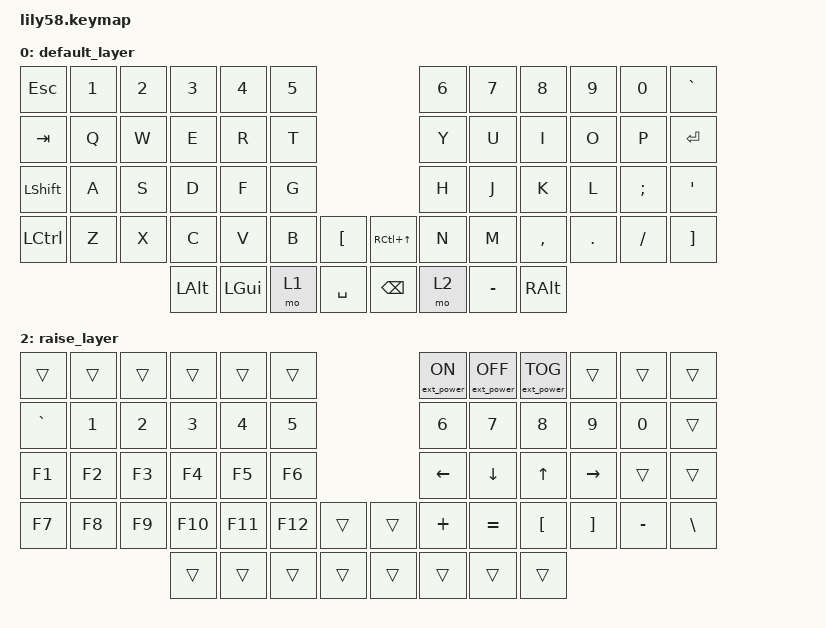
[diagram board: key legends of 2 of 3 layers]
/*
 * Copyright (c) 2020 The ZMK Contributors
 *
 * SPDX-License-Identifier: MIT
 */

#include <behaviors.dtsi>
#include <dt-bindings/zmk/bt.h>
#include <dt-bindings/zmk/ext_power.h>
#include <dt-bindings/zmk/keys.h>

/ {
    behaviors {
        td_mt: tap_dance_mod_tap {
            compatible = "zmk,behavior-tap-dance";
            label = "TAP_DANCE_MOD_TAP";
            #binding-cells = <0>;
            tapping-term-ms = <80>;
            bindings = <&mt LSHIFT CAPSLOCK>, <&kp LCTRL>;
        };

        td0: tap_dance_0 {
            compatible = "zmk,behavior-tap-dance";
            label = "TAP_DANCE_0";
            #binding-cells = <0>;
            tapping-term-ms = <80>;
            bindings = <&kp RSHIFT>, <&kp LCTRL>, <&kp ENTER>;
        };
    };

    macros {
        menu: menu {
            compatible = "zmk,behavior-macro";
            label = "new_macro";
            #binding-cells = <0>;
            bindings = <&kp RGUI &kp D>;
        };
    };

    keymap {
        compatible = "zmk,keymap";

        default_layer {
            // ------------------------------------------------------------------------------------------------------------
            // |  ESC  |  1  |  2  |  3   |  4   |  5   |                   |  6   |  7    |  8    |  9   |   0   |   `   |
            // |  TAB  |  Q  |  W  |  E   |  R   |  T   |                   |  Y   |  U    |  I    |  O   |   P   |   -   |
            // | CTRL   |A  |  S  |  D   |  F   |  G   |                   |  H   |  J    |  K    |  L   |   ;   |   '   |
            // | SHIFT |  Z  |  X  |  C   |  V   |  B   |   "["  |  |  "]"  |  N   |  M    |  ,    |  .   |   /   | SHIFT |
            //                     | ALT  | GUI  | LOWER|  SPACE |  | BSPC  | RAISE| ENTER | GUI   |

            bindings = <
&kp ESC     &kp N1  &kp N2  &kp N3        &kp N4    &kp N5                                &kp N6  &kp N7     &kp N8         &kp N9   &kp N0    &kp GRAVE
&kp TAB     &kp Q   &kp W   &kp E         &kp R     &kp T                                 &kp Y   &kp U      &kp I          &kp O    &kp P     &kp RETURN
&kp LSHIFT   &kp A   &kp S   &kp D         &kp F     &kp G                                 &kp H   &kp J      &kp K          &kp L    &kp SEMI  &kp SQT
&kp LCTRL  &kp Z   &kp X   &kp C         &kp V     &kp B   &kp LBKT     &kp RC(UP_ARROW)  &kp N   &kp M      &kp COMMA      &kp DOT  &kp FSLH  &kp RIGHT_BRACKET
                            &kp LEFT_ALT  &kp LGUI  &mo 1   &kp SPACE    &kp BACKSPACE    &mo 2   &kp MINUS  &kp RIGHT_ALT
            >;

            sensor-bindings = <&inc_dec_kp LC(LEFT_ARROW) LC(RIGHT_ARROW)>;
        };

        lower_layer {
            // ------------------------------------------------------------------------------------------------------------
            // | BTCLR | BT1 | BT2 |  BT3 |  BT4 |  BT5 |                   |      |       |       |      |       |       |
            // |  F1   |  F2 |  F3 |  F4  |  F5  |  F6  |                   |  F7  |  F8   |  F9   |  F10 |  F11  |  F12  |
            // |   `   |  !  |  @  |  #   |  $   |  %   |                   |  ^   |  &    |  *    |  (   |   )   |   ~   |
            // |   |  |  |  | |      |      |  |      |       |  _    |  +   |  {    |   }   |  "|"  |
            //                     |      |      |      |        |  |       |      |       |       |

            bindings = <
&bt BT_CLR    &bt BT_SEL 0  &bt BT_SEL 1  &bt BT_SEL 2  &bt BT_SEL 3  &bt BT_SEL 4                              &kp C_PREV  &kp C_PLAY_PAUSE  &kp C_NEXT       &kp C_BRIGHTNESS_DEC  &kp C_BRIGHTNESS_INC  &kp LS(PRINTSCREEN)
&trans        &trans        &kp LC(W)     &trans        &trans        &kp LC(T)                                 &trans      &kp LC(U)         &kp LC(I)        &kp LC(O)             &kp LC(P)             &trans
&kp GRAVE     &kp EXCL      &kp AT        &kp HASH      &kp DOLLAR    &kp PRCNT                                 &kp CARET   &kp AMPS          &kp KP_MULTIPLY  &kp LPAR              &kp RPAR              &kp TILDE
&kp CAPSLOCK  &kp LC(Z)     &kp LC(X)     &kp LC(C)     &kp LC(V)     &kp LC(B)     &trans    &kp C_PLAY_PAUSE  &kp UNDER   &kp PLUS          &kp LBRC         &kp RBRC              &kp PIPE              &kp EQUAL
                                          &trans        &trans        &trans        &trans    &kp DEL           &trans      &trans
            >;

            sensor-bindings = <&inc_dec_kp UP DOWN>;
        };

        raise_layer {
            // ------------------------------------------------------------------------------------------------------------
            // |       |     |     |      |      |      |                   |      |       |       |      |       |       |
            // |   `   |  1  |  2  |  3   |  4   |  5   |                   |  6   |   7   |   8   |  9   |   0   |       |
            // |   F1  |  F2 |  F3 |  F4  |  F5  |  F6  |                   |  <-  |   v   |  ^    |  ->  |       |       |
            // |   F7  |  F8 |  F9 |  F10 |  F11 |  F12 |        |  |       |  +   |   -   |   =   |  [   |   ]   |   \   |
            //                     |      |      |      |        |  |       |      |       |       |

            bindings = <
&trans     &trans  &trans  &trans   &trans   &trans                     &ext_power EP_ON  &ext_power EP_OFF  &ext_power EP_TOG  &trans     &trans     &trans
&kp GRAVE  &kp N1  &kp N2  &kp N3   &kp N4   &kp N5                     &kp N6            &kp N7             &kp N8             &kp N9     &kp N0     &trans
&kp F1     &kp F2  &kp F3  &kp F4   &kp F5   &kp F6                     &kp LEFT          &kp DOWN           &kp UP             &kp RIGHT  &trans     &trans
&kp F7     &kp F8  &kp F9  &kp F10  &kp F11  &kp F12  &trans    &trans  &kp PLUS          &kp EQUAL          &kp LBKT           &kp RBKT   &kp MINUS  &kp BSLH
                           &trans   &trans   &trans   &trans    &trans  &trans            &trans             &trans
            >;

            sensor-bindings = <&inc_dec_kp C_VOL_UP C_VOL_DN>;
        };
    };
};
